AUTOSAR XML (schema 4-0-3)
package /App_Uds
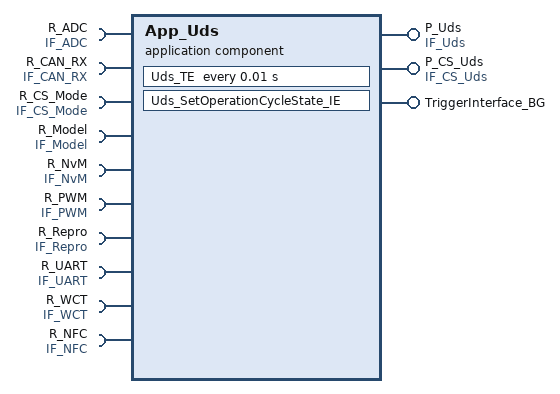
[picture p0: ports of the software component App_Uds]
  application sw component type App_Uds
    provide port P_Uds: nonqueued-sender-com-spec=Uds_STR, provided-interface=IF_Uds
    provide port P_CS_Uds: server-com-spec{operation=SetOperationCycleState, queue-length=1}, provided-interface=IF_CS_Uds
    10 x require port:
      R_ADC: nonqueued-receiver-com-spec=ADC_STR, required-interface=IF_ADC
      R_CAN_RX: nonqueued-receiver-com-spec=CAN_RX_STR, required-interface=IF_CAN_RX
      R_CS_Mode: required-interface=IF_CS_Mode  # None
      R_Model: nonqueued-receiver-com-spec=Model_STR, required-interface=IF_Model
      R_NvM: nonqueued-receiver-com-spec=NvM_STR, required-interface=IF_NvM  # None
      R_PWM: nonqueued-receiver-com-spec=PWM_STR, required-interface=IF_PWM
      R_Repro: nonqueued-receiver-com-spec=Repro_STR, required-interface=IF_Repro
      R_UART: nonqueued-receiver-com-spec=UART_STR, required-interface=IF_UART
      R_WCT: nonqueued-receiver-com-spec=WCT_STR, required-interface=IF_WCT  # None
      R_NFC: nonqueued-receiver-com-spec=NFC_STR, required-interface=IF_NFC
    provide port TriggerInterface_BG: provided-interface=TriggerInterface_BG
    behavior InternalBehaviors_DiagnosticService: data-type-mapping=[DcmApplicationUpdated, DataTypeMappingSet_WPC]
      timing event TE_Uds_TE: start-on-event=Uds_TE, period=0.01
      operation invoked event OIE_Uds_SetOperationCycleState_IE_P_CS_Uds_SetOperationCycleState: start-on-event=Uds_SetOperationCycleState_IE, operation=P_CS_Uds.SetOperationCycleState
      runnable Uds_TE: symbol=Uds_TE_Runnable
        data-receive-point-by-arguments:
          9 x access, all with scope=COMMUNICATION-INTER-ECU:
            DRPBA_Uds_TE_R_ADC_ADC_STR: accessed-variable=R_ADC.ADC_STR
            DRPBA_Uds_TE_R_CAN_RX_BCAN_RX_STR: accessed-variable=R_CAN_RX.CAN_RX_STR
            DRPBA_Uds_TE_R_Model_Model_COMM_STR: accessed-variable=R_Model.Model_STR
            DRPBA_Uds_TE_R_NvM_NvM_STR: accessed-variable=R_NvM.NvM_STR
            DRPBA_Uds_TE_R_PWM_PWM1_STR: accessed-variable=R_PWM.PWM_STR
            DRPBA_Uds_TE_R_Repro_Repro_STR: accessed-variable=R_Repro.Repro_STR
            DRPBA_Uds_TE_R_UART_UART_COMM_STR: accessed-variable=R_UART.UART_STR
            DRPBA_App_Uds_TE_R_NFC_NFC2_STR: accessed-variable=R_NFC.NFC_STR
            DRPBA_App_Uds_TE_R_WCT_WCT_STR: accessed-variable=R_WCT.WCT_STR
        data-send-points:
          access DSP_Uds_TE_P_Uds_Uds_STR: accessed-variable=P_Uds.Uds_STR, scope=COMMUNICATION-INTER-ECU
        external-triggering-point trigger=TriggerInterface_BG.Trigger_BG:
          ident ETP_Uds_TE_TriggerInterface_BG_Trigger_BG
        sync call SSCP_Uds_TE_R_CS_Mode_ApplicationInit: operation=R_CS_Mode.ApplicationInit
        sync call SSCP_Uds_TE_R_CS_Mode_ModeInit: operation=R_CS_Mode.ModeInit
        sync call SSCP_Uds_TE_R_CS_Mode_NvMInit: operation=R_CS_Mode.NvMInit
      runnable Uds_SetOperationCycleState_IE: symbol=Uds_SetOperationCycleState_IE_Runnable
      swc service dependency SwcServiceDependency0
        assigned-ports:
          port-prototype=modeNotificationPort_SessionControl, role=Custom
          port-prototype=modeNotificationPort_ApplicationUpdated, role=Custom
          port-prototype=DcmControlDTCSetting, role=Custom
          port-prototype=DcmModeRapidPowerShutDown, role=Custom
          port-prototype=DcmCommunicationControl_0, role=Custom
        service-needs:
          bsw mgr needs BswMgrNeeds
  client server interface IF_CS_Uds
    operation SetOperationCycleState
      arg sort: type=uint8, direction=IN, server-argument-impl-policy=USE-ARGUMENT-TYPE
      arg value: type=uint8, direction=IN, server-argument-impl-policy=USE-ARGUMENT-TYPE
  sender receiver interface IF_Uds  # NFC SWC Output
    data Uds_STR: type=IDT_Uds_STR
